AUTOSAR XML (schema 00045)
package /Med
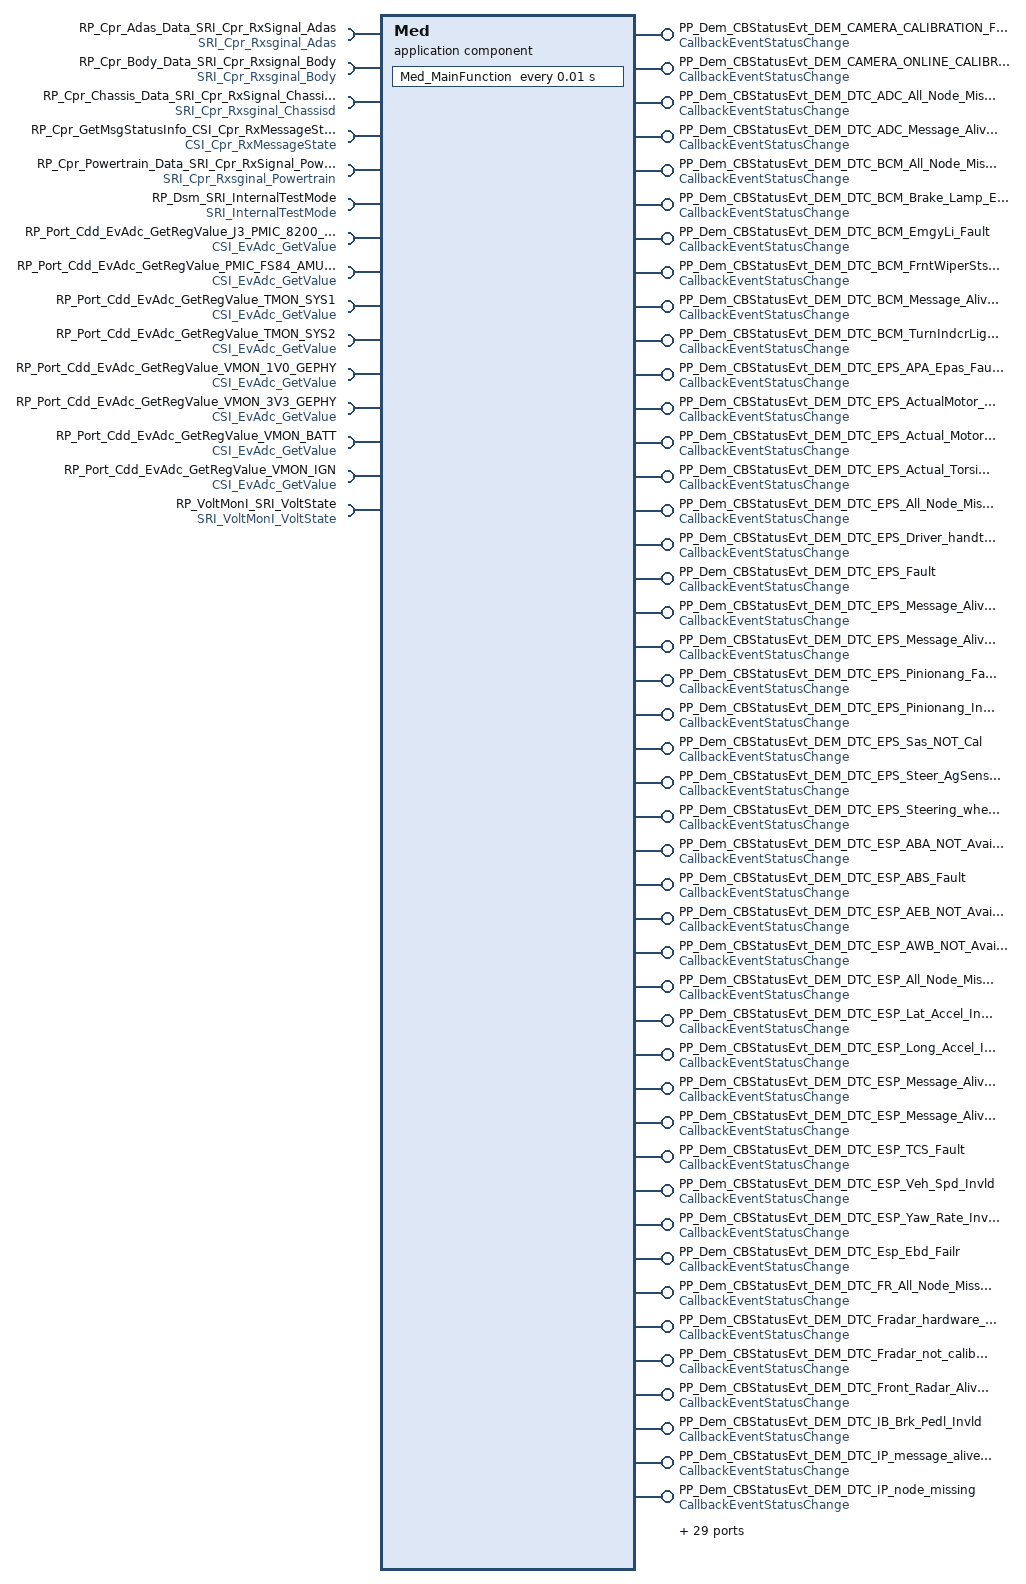
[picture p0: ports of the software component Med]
  application sw component type Med  # Mcu Error Dection
    73 x provide port, all with provided-interface=CallbackEventStatusChange:
      PP_Dem_CBStatusEvt_DEM_CAMERA_CALIBRATION_FAILURE
      PP_Dem_CBStatusEvt_DEM_CAMERA_ONLINE_CALIBRATION_FAILURE
      PP_Dem_CBStatusEvt_DEM_DTC_ADC_All_Node_Missing
      PP_Dem_CBStatusEvt_DEM_DTC_ADC_Message_Alive_Counter_Error
      PP_Dem_CBStatusEvt_DEM_DTC_BCM_All_Node_Missing
      PP_Dem_CBStatusEvt_DEM_DTC_BCM_Brake_Lamp_Error
      PP_Dem_CBStatusEvt_DEM_DTC_BCM_EmgyLi_Fault
      PP_Dem_CBStatusEvt_DEM_DTC_BCM_FrntWiperSts_Fault
      PP_Dem_CBStatusEvt_DEM_DTC_BCM_Message_Alive_Counter_Error_40ms
      PP_Dem_CBStatusEvt_DEM_DTC_BCM_TurnIndcrLight_Fault
      PP_Dem_CBStatusEvt_DEM_DTC_EPS_APA_Epas_Fault
      PP_Dem_CBStatusEvt_DEM_DTC_EPS_ActualMotor_Invld
      PP_Dem_CBStatusEvt_DEM_DTC_EPS_Actual_Motor_Torq_Invld
      PP_Dem_CBStatusEvt_DEM_DTC_EPS_Actual_TorsionTorq_Invld
      PP_Dem_CBStatusEvt_DEM_DTC_EPS_All_Node_Missing
      PP_Dem_CBStatusEvt_DEM_DTC_EPS_Driver_handtorque_invalid
      PP_Dem_CBStatusEvt_DEM_DTC_EPS_Fault
      PP_Dem_CBStatusEvt_DEM_DTC_EPS_Message_Alive_Counter_Error_10ms
      PP_Dem_CBStatusEvt_DEM_DTC_EPS_Message_Alive_Counter_Error_20ms
      PP_Dem_CBStatusEvt_DEM_DTC_EPS_Pinionang_Fault
      PP_Dem_CBStatusEvt_DEM_DTC_EPS_Pinionang_Invld
      PP_Dem_CBStatusEvt_DEM_DTC_EPS_Sas_NOT_Cal
      PP_Dem_CBStatusEvt_DEM_DTC_EPS_Steer_AgSens_Fault
      PP_Dem_CBStatusEvt_DEM_DTC_EPS_Steering_wheelvibration_failure
      PP_Dem_CBStatusEvt_DEM_DTC_ESP_ABA_NOT_Available
      PP_Dem_CBStatusEvt_DEM_DTC_ESP_ABS_Fault
      PP_Dem_CBStatusEvt_DEM_DTC_ESP_AEB_NOT_Available
      PP_Dem_CBStatusEvt_DEM_DTC_ESP_AWB_NOT_Available
      PP_Dem_CBStatusEvt_DEM_DTC_ESP_All_Node_Missing
      PP_Dem_CBStatusEvt_DEM_DTC_ESP_Lat_Accel_Invld
      PP_Dem_CBStatusEvt_DEM_DTC_ESP_Long_Accel_Invld
      PP_Dem_CBStatusEvt_DEM_DTC_ESP_Message_Alive_Counter_Error
      PP_Dem_CBStatusEvt_DEM_DTC_ESP_Message_Alive_Counter_Error_100ms
      PP_Dem_CBStatusEvt_DEM_DTC_ESP_TCS_Fault
      PP_Dem_CBStatusEvt_DEM_DTC_ESP_Veh_Spd_Invld
      PP_Dem_CBStatusEvt_DEM_DTC_ESP_Yaw_Rate_Invld
      PP_Dem_CBStatusEvt_DEM_DTC_Esp_Ebd_Failr
      PP_Dem_CBStatusEvt_DEM_DTC_FR_All_Node_Missing
      PP_Dem_CBStatusEvt_DEM_DTC_Fradar_hardware_error
      PP_Dem_CBStatusEvt_DEM_DTC_Fradar_not_calibration_or_blockage
      PP_Dem_CBStatusEvt_DEM_DTC_Front_Radar_Alive_Counter_Error
      PP_Dem_CBStatusEvt_DEM_DTC_IB_Brk_Pedl_Invld
      PP_Dem_CBStatusEvt_DEM_DTC_IP_message_alive_counter_error
      PP_Dem_CBStatusEvt_DEM_DTC_IP_node_missing
      PP_Dem_CBStatusEvt_DEM_DTC_IP_warning_invalid
      PP_Dem_CBStatusEvt_DEM_DTC_J3_Camera_Blockage
      PP_Dem_CBStatusEvt_DEM_DTC_J3_Camera_Error
      PP_Dem_CBStatusEvt_DEM_DTC_J3_SOC_CPU_Error_PWM_Missing
      PP_Dem_CBStatusEvt_DEM_DTC_J3_SOC_Perception_Error
      PP_Dem_CBStatusEvt_DEM_DTC_J3_SOC_Safetylib_Error
      PP_Dem_CBStatusEvt_DEM_DTC_J3_SOC_System_Service_Error
      PP_Dem_CBStatusEvt_DEM_DTC_J3_Time_Sync_Error
      PP_Dem_CBStatusEvt_DEM_DTC_MCU_TEMP_INITIAL_HIGH
      PP_Dem_CBStatusEvt_DEM_DTC_Private_CAN_Bus_Off
      PP_Dem_CBStatusEvt_DEM_DTC_Public_CAN_Bus_Off
      PP_Dem_CBStatusEvt_DEM_DTC_RLR_Message_Alive_Counter_Error
      PP_Dem_CBStatusEvt_DEM_DTC_SRS_All_Node_Missing
      PP_Dem_CBStatusEvt_DEM_DTC_SRS_Drvr_BucSwt_Invld
      PP_Dem_CBStatusEvt_DEM_DTC_SRS_Message_Alive_Counter_Error
      PP_Dem_CBStatusEvt_DEM_DTC_VCU_Accr_Pedl_Posn_Invld
      PP_Dem_CBStatusEvt_DEM_DTC_VCU_All_Node_Missing
      PP_Dem_CBStatusEvt_DEM_DTC_VCU_Gear_Posn_Invld
      PP_Dem_CBStatusEvt_DEM_DTC_VCU_Message_Alive_Counter_Error
      PP_Dem_CBStatusEvt_DEM_DTC_Whl_Spd_Data_Invld
      PP_Dem_CBStatusEvt_DEM_DTC_Whl_Spd_Dir_Invld
      PP_Dem_CBStatusEvt_DEM_DTC_Whl_Spd_Pls_Invld
      PP_Dem_CBStatusEvt_DEM_J3_SYS_KERNEL_SW
      PP_Dem_CBStatusEvt_DEM_MCU_TEMP_EXT_HIGH
      PP_Dem_CBStatusEvt_DEM_MCU_TEMP_EXT_LOW
      PP_Dem_CBStatusEvt_DEM_SOCJ3_TEMP_EXT_HIGH
      PP_Dem_CBStatusEvt_DEM_VMON_BATT_HIGH
      PP_Dem_CBStatusEvt_DEM_VMON_BATT_LOW
      PP_Dem_CBStatusEvt_SPI_E_HARDWARE_ERROR
    15 x require port:
      RP_Cpr_Adas_Data_SRI_Cpr_RxSignal_Adas: required-interface=SRI_Cpr_Rxsginal_Adas
      RP_Cpr_Body_Data_SRI_Cpr_Rxsignal_Body: required-interface=SRI_Cpr_Rxsginal_Body
      RP_Cpr_Chassis_Data_SRI_Cpr_RxSignal_Chassisd: required-interface=SRI_Cpr_Rxsginal_Chassisd
      RP_Cpr_GetMsgStatusInfo_CSI_Cpr_RxMessageState: required-interface=CSI_Cpr_RxMessageState
      RP_Cpr_Powertrain_Data_SRI_Cpr_RxSignal_Powertrain: required-interface=SRI_Cpr_Rxsginal_Powertrain
      RP_Dsm_SRI_InternalTestMode: required-interface=SRI_InternalTestMode
      RP_Port_Cdd_EvAdc_GetRegValue_J3_PMIC_8200_AMUX_OUT: required-interface=CSI_EvAdc_GetValue
      RP_Port_Cdd_EvAdc_GetRegValue_PMIC_FS84_AMUX_OUT0: required-interface=CSI_EvAdc_GetValue
      RP_Port_Cdd_EvAdc_GetRegValue_TMON_SYS1: required-interface=CSI_EvAdc_GetValue
      RP_Port_Cdd_EvAdc_GetRegValue_TMON_SYS2: required-interface=CSI_EvAdc_GetValue
      RP_Port_Cdd_EvAdc_GetRegValue_VMON_1V0_GEPHY: required-interface=CSI_EvAdc_GetValue
      RP_Port_Cdd_EvAdc_GetRegValue_VMON_3V3_GEPHY: required-interface=CSI_EvAdc_GetValue
      RP_Port_Cdd_EvAdc_GetRegValue_VMON_BATT: required-interface=CSI_EvAdc_GetValue
      RP_Port_Cdd_EvAdc_GetRegValue_VMON_IGN: required-interface=CSI_EvAdc_GetValue
      RP_VoltMonI_SRI_VoltState: required-interface=SRI_VoltMonI_VoltState
    behavior Med_IB: handle-termination-and-restart=NO-SUPPORT
      init event InitEvent_Med_InitFunction: start-on-event=Med_InitFunction
      timing event TimingEvent_Med_Mainfunction: start-on-event=Med_MainFunction, period=0.01
      73 x operation invoked event:
        oie_PP_Dem_CBStatusEvt_DEM_CAMERA_CALIBRATION_FAILURE_EventStatusChanged: start-on-event=Med_u_CBStatusEvt_DEM_CAMERA_CALIBRATION_FAILURE, operation=PP_Dem_CBStatusEvt_DEM_CAMERA_CALIBRATION_FAILURE.EventStatusChanged
        oie_PP_Dem_CBStatusEvt_DEM_CAMERA_ONLINE_CALIBRATION_FAILURE_EventStatusChanged: start-on-event=Med_u_CBStatusEvt_DEM_CAMERA_ONLINE_CALIBRATION_FAILURE, operation=PP_Dem_CBStatusEvt_DEM_CAMERA_ONLINE_CALIBRATION_FAILURE.EventStatusChanged
        oie_PP_Dem_CBStatusEvt_DEM_DTC_ADC_All_Node_Missing_EventStatusChanged: start-on-event=Med_u_CBStatusEvt_DEM_DTC_ADC_All_Node_Missing, operation=PP_Dem_CBStatusEvt_DEM_DTC_ADC_All_Node_Missing.EventStatusChanged
        oie_PP_Dem_CBStatusEvt_DEM_DTC_ADC_Message_Alive_Counter_Error_EventStatusChanged: start-on-event=Med_u_CBStatusEvt_DEM_DTC_ADC_Message_Alive_Counter_Error, operation=PP_Dem_CBStatusEvt_DEM_DTC_ADC_Message_Alive_Counter_Error.EventStatusChanged
        oie_PP_Dem_CBStatusEvt_DEM_DTC_BCM_All_Node_Missing_EventStatusChanged: start-on-event=Med_u_CBStatusEvt_DEM_DTC_BCM_All_Node_Missing, operation=PP_Dem_CBStatusEvt_DEM_DTC_BCM_All_Node_Missing.EventStatusChanged
        oie_PP_Dem_CBStatusEvt_DEM_DTC_BCM_Brake_Lamp_Error_EventStatusChanged: start-on-event=Med_u_CBStatusEvt_DEM_DTC_BCM_Brake_Lamp_Error, operation=PP_Dem_CBStatusEvt_DEM_DTC_BCM_Brake_Lamp_Error.EventStatusChanged
        oie_PP_Dem_CBStatusEvt_DEM_DTC_BCM_EmgyLi_Fault_EventStatusChanged: start-on-event=Med_u_CBStatusEvt_DEM_DTC_BCM_EmgyLi_Fault, operation=PP_Dem_CBStatusEvt_DEM_DTC_BCM_EmgyLi_Fault.EventStatusChanged
        oie_PP_Dem_CBStatusEvt_DEM_DTC_BCM_FrntWiperSts_Fault_EventStatusChanged: start-on-event=Med_u_CBStatusEvt_DEM_DTC_BCM_FrntWiperSts_Fault, operation=PP_Dem_CBStatusEvt_DEM_DTC_BCM_FrntWiperSts_Fault.EventStatusChanged
        oie_PP_Dem_CBStatusEvt_DEM_DTC_BCM_Message_Alive_Counter_Error_40ms_EventStatusChanged: start-on-event=Med_u_CBStatusEvt_DEM_DTC_BCM_Message_Alive_Counter_Error_40ms, operation=PP_Dem_CBStatusEvt_DEM_DTC_BCM_Message_Alive_Counter_Error_40ms.EventStatusChanged
        oie_PP_Dem_CBStatusEvt_DEM_DTC_BCM_Turn_Indcr_Light_Fault_EventStatusChanged: start-on-event=Med_u_CBStatusEvt_DEM_DTC_BCM_TurnIndcrLight_Fault, operation=PP_Dem_CBStatusEvt_DEM_DTC_BCM_TurnIndcrLight_Fault.EventStatusChanged
        oie_PP_Dem_CBStatusEvt_DEM_DTC_EPS_APA_Epas_Fault_EventStatusChanged: start-on-event=Med_u_CBStatusEvt_DEM_DTC_EPS_APA_Epas_Fault, operation=PP_Dem_CBStatusEvt_DEM_DTC_EPS_APA_Epas_Fault.EventStatusChanged
        oie_PP_Dem_CBStatusEvt_DEM_DTC_EPS_ActualMotor_Invld_EventStatusChanged: start-on-event=Med_u_CBStatusEvt_DEM_DTC_EPS_ActualMotor_Invld, operation=PP_Dem_CBStatusEvt_DEM_DTC_EPS_ActualMotor_Invld.EventStatusChanged
        oie_PP_Dem_CBStatusEvt_DEM_DTC_EPS_Actual_Motor_Torq_Invld_EventStatusChanged: start-on-event=Med_u_CBStatusEvt_DEM_DTC_EPS_Actual_Motor_Torq_Invld, operation=PP_Dem_CBStatusEvt_DEM_DTC_EPS_Actual_Motor_Torq_Invld.EventStatusChanged
        oie_PP_Dem_CBStatusEvt_DEM_DTC_EPS_Actual_TorsionTorq_Invld_EventStatusChanged: start-on-event=Med_u_CBStatusEvt_DEM_DTC_EPS_Actual_TorsionTorq_Invld, operation=PP_Dem_CBStatusEvt_DEM_DTC_EPS_Actual_TorsionTorq_Invld.EventStatusChanged
        oie_PP_Dem_CBStatusEvt_DEM_DTC_EPS_All_Node_Missing_EventStatusChanged: start-on-event=Med_u_CBStatusEvt_DEM_DTC_EPS_All_Node_Missing, operation=PP_Dem_CBStatusEvt_DEM_DTC_EPS_All_Node_Missing.EventStatusChanged
        oie_PP_Dem_CBStatusEvt_DEM_DTC_EPS_Driver_handtorque_invalid_EventStatusChanged: start-on-event=Med_u_CBStatusEvt_DEM_DTC_EPS_Driver_handtorque_invalid, operation=PP_Dem_CBStatusEvt_DEM_DTC_EPS_Driver_handtorque_invalid.EventStatusChanged
        oie_PP_Dem_CBStatusEvt_DEM_DTC_EPS_Fault_EventStatusChanged: start-on-event=Med_u_CBStatusEvt_DEM_DTC_EPS_Fault, operation=PP_Dem_CBStatusEvt_DEM_DTC_EPS_Fault.EventStatusChanged
        oie_PP_Dem_CBStatusEvt_DEM_DTC_EPS_Message_Alive_Counter_Error_10ms_EventStatusChanged: start-on-event=Med_u_CBStatusEvt_DEM_DTC_EPS_Message_Alive_Counter_Error_10ms, operation=PP_Dem_CBStatusEvt_DEM_DTC_EPS_Message_Alive_Counter_Error_10ms.EventStatusChanged
        oie_PP_Dem_CBStatusEvt_DEM_DTC_EPS_Message_Alive_Counter_Error_20ms_EventStatusChanged: start-on-event=Med_u_CBStatusEvt_DEM_DTC_EPS_Message_Alive_Counter_Error_20ms, operation=PP_Dem_CBStatusEvt_DEM_DTC_EPS_Message_Alive_Counter_Error_20ms.EventStatusChanged
        oie_PP_Dem_CBStatusEvt_DEM_DTC_EPS_Pinionang_Fault_EventStatusChanged: start-on-event=Med_u_CBStatusEvt_DEM_DTC_EPS_Pinionang_Fault, operation=PP_Dem_CBStatusEvt_DEM_DTC_EPS_Pinionang_Fault.EventStatusChanged
        oie_PP_Dem_CBStatusEvt_DEM_DTC_EPS_Pinionang_Invld_EventStatusChanged: start-on-event=Med_u_CBStatusEvt_DEM_DTC_EPS_Pinionang_Invld, operation=PP_Dem_CBStatusEvt_DEM_DTC_EPS_Pinionang_Invld.EventStatusChanged
        oie_PP_Dem_CBStatusEvt_DEM_DTC_EPS_Sas_NOT_Cal_EventStatusChanged: start-on-event=Med_u_CBStatusEvt_DEM_DTC_EPS_Sas_NOT_Cal, operation=PP_Dem_CBStatusEvt_DEM_DTC_EPS_Sas_NOT_Cal.EventStatusChanged
        oie_PP_Dem_CBStatusEvt_DEM_DTC_EPS_Steer_AgSens_Fault_EventStatusChanged: start-on-event=Med_u_CBStatusEvt_DEM_DTC_EPS_Steer_AgSens_Fault, operation=PP_Dem_CBStatusEvt_DEM_DTC_EPS_Steer_AgSens_Fault.EventStatusChanged
        oie_PP_Dem_CBStatusEvt_DEM_DTC_EPS_Steering_wheelvibration_failure_EventStatusChanged: start-on-event=Med_u_CBStatusEvt_DEM_DTC_EPS_Steering_wheelvibration_failure, operation=PP_Dem_CBStatusEvt_DEM_DTC_EPS_Steering_wheelvibration_failure.EventStatusChanged
        oie_PP_Dem_CBStatusEvt_DEM_DTC_ESP_ABA_NOT_Available_EventStatusChanged: start-on-event=Med_u_CBStatusEvt_DEM_DTC_ESP_ABA_NOT_Available, operation=PP_Dem_CBStatusEvt_DEM_DTC_ESP_ABA_NOT_Available.EventStatusChanged
        oie_PP_Dem_CBStatusEvt_DEM_DTC_ESP_ABS_Fault_EventStatusChanged: start-on-event=Med_u_CBStatusEvt_DEM_DTC_ESP_ABS_Fault, operation=PP_Dem_CBStatusEvt_DEM_DTC_ESP_ABS_Fault.EventStatusChanged
        oie_PP_Dem_CBStatusEvt_DEM_DTC_ESP_AEB_NOT_Available_EventStatusChanged: start-on-event=Med_u_CBStatusEvt_DEM_DTC_ESP_AEB_NOT_Available, operation=PP_Dem_CBStatusEvt_DEM_DTC_ESP_AEB_NOT_Available.EventStatusChanged
        oie_PP_Dem_CBStatusEvt_DEM_DTC_ESP_AWB_NOT_Available_EventStatusChanged: start-on-event=Med_u_CBStatusEvt_DEM_DTC_ESP_AWB_NOT_Available, operation=PP_Dem_CBStatusEvt_DEM_DTC_ESP_AWB_NOT_Available.EventStatusChanged
        oie_PP_Dem_CBStatusEvt_DEM_DTC_ESP_All_Node_Missing_EventStatusChanged: start-on-event=Med_u_CBStatusEvt_DEM_DTC_ESP_All_Node_Missing, operation=PP_Dem_CBStatusEvt_DEM_DTC_ESP_All_Node_Missing.EventStatusChanged
        oie_PP_Dem_CBStatusEvt_DEM_DTC_ESP_Lat_Accel_Invld_EventStatusChanged: start-on-event=Med_u_CBStatusEvt_DEM_DTC_ESP_Lat_Accel_Invld, operation=PP_Dem_CBStatusEvt_DEM_DTC_ESP_Lat_Accel_Invld.EventStatusChanged
        oie_PP_Dem_CBStatusEvt_DEM_DTC_ESP_Long_Accel_Invld_EventStatusChanged: start-on-event=Med_u_CBStatusEvt_DEM_DTC_ESP_Long_Accel_Invld, operation=PP_Dem_CBStatusEvt_DEM_DTC_ESP_Long_Accel_Invld.EventStatusChanged
        oie_PP_Dem_CBStatusEvt_DEM_DTC_ESP_Message_Alive_Counter_Error_100ms_EventStatusChanged: start-on-event=Med_u_CBStatusEvt_DEM_DTC_ESP_Message_Alive_Counter_Error_100ms, operation=PP_Dem_CBStatusEvt_DEM_DTC_ESP_Message_Alive_Counter_Error_100ms.EventStatusChanged
        oie_PP_Dem_CBStatusEvt_DEM_DTC_ESP_Message_Alive_Counter_Error_EventStatusChanged: start-on-event=Med_u_CBStatusEvt_DEM_DTC_ESP_Message_Alive_Counter_Error, operation=PP_Dem_CBStatusEvt_DEM_DTC_ESP_Message_Alive_Counter_Error.EventStatusChanged
        oie_PP_Dem_CBStatusEvt_DEM_DTC_ESP_TCS_Fault_EventStatusChanged: start-on-event=Med_u_CBStatusEvt_DEM_DTC_ESP_TCS_Fault, operation=PP_Dem_CBStatusEvt_DEM_DTC_ESP_TCS_Fault.EventStatusChanged
        oie_PP_Dem_CBStatusEvt_DEM_DTC_ESP_Veh_Spd_Invld_EventStatusChanged: start-on-event=Med_u_CBStatusEvt_DEM_DTC_ESP_Veh_Spd_Invld, operation=PP_Dem_CBStatusEvt_DEM_DTC_ESP_Veh_Spd_Invld.EventStatusChanged
        oie_PP_Dem_CBStatusEvt_DEM_DTC_ESP_Yaw_Rate_Invld_EventStatusChanged: start-on-event=Med_u_CBStatusEvt_DEM_DTC_ESP_Yaw_Rate_Invld, operation=PP_Dem_CBStatusEvt_DEM_DTC_ESP_Yaw_Rate_Invld.EventStatusChanged
        oie_PP_Dem_CBStatusEvt_DEM_DTC_Esp_Ebd_Failr_EventStatusChanged: start-on-event=Med_u_CBStatusEvt_DEM_DTC_ESP_Ebd_Failr, operation=PP_Dem_CBStatusEvt_DEM_DTC_Esp_Ebd_Failr.EventStatusChanged
        oie_PP_Dem_CBStatusEvt_DEM_DTC_FR_All_Node_Missing_EventStatusChanged: start-on-event=Med_u_CBStatusEvt_DEM_DTC_FR_All_Node_Missing, operation=PP_Dem_CBStatusEvt_DEM_DTC_FR_All_Node_Missing.EventStatusChanged
        oie_PP_Dem_CBStatusEvt_DEM_DTC_Fradar_hardware_error_EventStatusChanged: start-on-event=Med_u_CBStatusEvt_DEM_DTC_Fradar_hardware_error, operation=PP_Dem_CBStatusEvt_DEM_DTC_Fradar_hardware_error.EventStatusChanged
        oie_PP_Dem_CBStatusEvt_DEM_DTC_Fradar_not_calibration_or_blockage_EventStatusChanged: start-on-event=Med_u_CBStatusEvt_DEM_DTC_Fradar_not_calibration_or_blockage, operation=PP_Dem_CBStatusEvt_DEM_DTC_Fradar_not_calibration_or_blockage.EventStatusChanged
        oie_PP_Dem_CBStatusEvt_DEM_DTC_Front_Radar_Alive_Counter_Error_EventStatusChanged: start-on-event=Med_u_CBStatusEvt_DEM_DTC_Front_Radar_Alive_Counter_Error, operation=PP_Dem_CBStatusEvt_DEM_DTC_Front_Radar_Alive_Counter_Error.EventStatusChanged
        oie_PP_Dem_CBStatusEvt_DEM_DTC_IB_Brk_Pedl_Invld_EventStatusChanged: start-on-event=Med_u_CBStatusEvt_DEM_DTC_IB_Brk_Pedl_Invld, operation=PP_Dem_CBStatusEvt_DEM_DTC_IB_Brk_Pedl_Invld.EventStatusChanged
        oie_PP_Dem_CBStatusEvt_DEM_DTC_IP_message_alive_counter_error_EventStatusChanged: start-on-event=Med_u_CBStatusEvt_DEM_DTC_IP_message_alive_counter_error, operation=PP_Dem_CBStatusEvt_DEM_DTC_IP_message_alive_counter_error.EventStatusChanged
        oie_PP_Dem_CBStatusEvt_DEM_DTC_IP_node_missing_EventStatusChanged: start-on-event=Med_u_CBStatusEvt_DEM_DTC_IP_node_missing, operation=PP_Dem_CBStatusEvt_DEM_DTC_IP_node_missing.EventStatusChanged
        oie_PP_Dem_CBStatusEvt_DEM_DTC_IP_warning_invalid_EventStatusChanged: start-on-event=Med_u_CBStatusEvt_DEM_DTC_IP_warning_invalid, operation=PP_Dem_CBStatusEvt_DEM_DTC_IP_warning_invalid.EventStatusChanged
        oie_PP_Dem_CBStatusEvt_DEM_DTC_J3_Camera_Blockage_EventStatusChanged: start-on-event=Med_u_CBStatusEvt_DEM_DTC_J3_Camera_Blockage, operation=PP_Dem_CBStatusEvt_DEM_DTC_J3_Camera_Blockage.EventStatusChanged
        oie_PP_Dem_CBStatusEvt_DEM_DTC_J3_Camera_Error_EventStatusChanged: start-on-event=Med_u_CBStatusEvt_DEM_DTC_J3_Camera_Error, operation=PP_Dem_CBStatusEvt_DEM_DTC_J3_Camera_Error.EventStatusChanged
        oie_PP_Dem_CBStatusEvt_DEM_DTC_J3_SOC_CPU_Error_PWM_Missing_EventStatusChanged: start-on-event=Med_u_CBStatusEvt_DEM_DTC_J3_SOC_CPU_Error_PWM_Missing, operation=PP_Dem_CBStatusEvt_DEM_DTC_J3_SOC_CPU_Error_PWM_Missing.EventStatusChanged
        oie_PP_Dem_CBStatusEvt_DEM_DTC_J3_SOC_Perception_Error_EventStatusChanged: start-on-event=Med_u_CBStatusEvt_DEM_DTC_J3_SOC_Perception_Error, operation=PP_Dem_CBStatusEvt_DEM_DTC_J3_SOC_Perception_Error.EventStatusChanged
        oie_PP_Dem_CBStatusEvt_DEM_DTC_J3_SOC_Safetylib_Error_EventStatusChanged: start-on-event=Med_u_CBStatusEvt_DEM_DTC_J3_SOC_Safetylib_Error, operation=PP_Dem_CBStatusEvt_DEM_DTC_J3_SOC_Safetylib_Error.EventStatusChanged
        oie_PP_Dem_CBStatusEvt_DEM_DTC_J3_SOC_System_Service_Error_EventStatusChanged: start-on-event=Med_u_CBStatusEvt_DEM_DTC_J3_SOC_System_Service_Error, operation=PP_Dem_CBStatusEvt_DEM_DTC_J3_SOC_System_Service_Error.EventStatusChanged
        oie_PP_Dem_CBStatusEvt_DEM_DTC_J3_Time_Sync_Error_EventStatusChanged: start-on-event=Med_u_CBStatusEvt_DEM_DTC_J3_Time_Sync_Error, operation=PP_Dem_CBStatusEvt_DEM_DTC_J3_Time_Sync_Error.EventStatusChanged
        oie_PP_Dem_CBStatusEvt_DEM_DTC_MCU_TEMP_INITIAL_HIGH_EventStatusChanged: start-on-event=Med_u_CBStatusEvt_DEM_DTC_MCU_TEMP_INITIAL_HIGH, operation=PP_Dem_CBStatusEvt_DEM_DTC_MCU_TEMP_INITIAL_HIGH.EventStatusChanged
        oie_PP_Dem_CBStatusEvt_DEM_DTC_Private_CAN_Bus_Off_EventStatusChanged: start-on-event=Med_u_CBStatusEvt_DEM_DTC_Private_CAN_Bus_Off, operation=PP_Dem_CBStatusEvt_DEM_DTC_Private_CAN_Bus_Off.EventStatusChanged
        oie_PP_Dem_CBStatusEvt_DEM_DTC_Public_CAN_Bus_Off_EventStatusChanged: start-on-event=Med_u_CBStatusEvt_DEM_DTC_Public_CAN_Bus_Off, operation=PP_Dem_CBStatusEvt_DEM_DTC_Public_CAN_Bus_Off.EventStatusChanged
        oie_PP_Dem_CBStatusEvt_DEM_DTC_RLR_Message_Alive_Counter_Error_EventStatusChanged: start-on-event=Med_u_CBStatusEvt_DEM_DTC_RLR_Message_Alive_Counter_Error, operation=PP_Dem_CBStatusEvt_DEM_DTC_RLR_Message_Alive_Counter_Error.EventStatusChanged
        oie_PP_Dem_CBStatusEvt_DEM_DTC_SRS_All_Node_Missing_EventStatusChanged: start-on-event=Med_u_CBStatusEvt_DEM_DTC_SRS_All_Node_Missing, operation=PP_Dem_CBStatusEvt_DEM_DTC_SRS_All_Node_Missing.EventStatusChanged
        oie_PP_Dem_CBStatusEvt_DEM_DTC_SRS_Drvr_BucSwt_Invld_EventStatusChanged: start-on-event=Med_u_CBStatusEvt_DEM_DTC_SRS_Drvr_BucSwt_Invld, operation=PP_Dem_CBStatusEvt_DEM_DTC_SRS_Drvr_BucSwt_Invld.EventStatusChanged
        oie_PP_Dem_CBStatusEvt_DEM_DTC_SRS_Message_Alive_Counter_Error_EventStatusChanged: start-on-event=Med_u_CBStatusEvt_DEM_DTC_SRS_Message_Alive_Counter_Error, operation=PP_Dem_CBStatusEvt_DEM_DTC_SRS_Message_Alive_Counter_Error.EventStatusChanged
        oie_PP_Dem_CBStatusEvt_DEM_DTC_VCU_Accr_Pedl_Posn_Invld_EventStatusChanged: start-on-event=Med_u_CBStatusEvt_DEM_DTC_VCU_Accr_Pedl_Posn_Invld, operation=PP_Dem_CBStatusEvt_DEM_DTC_VCU_Accr_Pedl_Posn_Invld.EventStatusChanged
        oie_PP_Dem_CBStatusEvt_DEM_DTC_VCU_All_Node_Missing_EventStatusChanged: start-on-event=Med_u_CBStatusEvt_DEM_DTC_VCU_All_Node_Missing, operation=PP_Dem_CBStatusEvt_DEM_DTC_VCU_All_Node_Missing.EventStatusChanged
        oie_PP_Dem_CBStatusEvt_DEM_DTC_VCU_Gear_Posn_Invld_EventStatusChanged: start-on-event=Med_u_CBStatusEvt_DEM_DTC_VCU_Gear_Posn_Invld, operation=PP_Dem_CBStatusEvt_DEM_DTC_VCU_Gear_Posn_Invld.EventStatusChanged
        oie_PP_Dem_CBStatusEvt_DEM_DTC_VCU_Message_Alive_Counter_Error_EventStatusChanged: start-on-event=Med_u_CBStatusEvt_DEM_DTC_VCU_Message_Alive_Counter_Error, operation=PP_Dem_CBStatusEvt_DEM_DTC_VCU_Message_Alive_Counter_Error.EventStatusChanged
        oie_PP_Dem_CBStatusEvt_DEM_DTC_Whl_Spd_Data_Invld_EventStatusChanged: start-on-event=Med_u_CBStatusEvt_DEM_DTC_Whl_Spd_Data_Invld, operation=PP_Dem_CBStatusEvt_DEM_DTC_Whl_Spd_Data_Invld.EventStatusChanged
        oie_PP_Dem_CBStatusEvt_DEM_DTC_Whl_Spd_Dir_Invld_EventStatusChanged: start-on-event=Med_u_CBStatusEvt_DEM_DTC_Whl_Spd_Dir_Invld, operation=PP_Dem_CBStatusEvt_DEM_DTC_Whl_Spd_Dir_Invld.EventStatusChanged
        oie_PP_Dem_CBStatusEvt_DEM_DTC_Whl_Spd_Pls_Invld_EventStatusChanged: start-on-event=Med_u_CBStatusEvt_DEM_DTC_Whl_Spd_Pls_Invld, operation=PP_Dem_CBStatusEvt_DEM_DTC_Whl_Spd_Pls_Invld.EventStatusChanged
        oie_PP_Dem_CBStatusEvt_DEM_J3_SYS_KERNEL_SW_EventStatusChanged: start-on-event=Med_u_CBStatusEvt_DEM_J3_SYS_KERNEL_SW, operation=PP_Dem_CBStatusEvt_DEM_J3_SYS_KERNEL_SW.EventStatusChanged
        oie_PP_Dem_CBStatusEvt_DEM_MCU_TEMP_EXT_HIGH_EventStatusChanged: start-on-event=Med_u_CBStatusEvt_DEM_MCU_TEMP_EXT_HIGH, operation=PP_Dem_CBStatusEvt_DEM_MCU_TEMP_EXT_HIGH.EventStatusChanged
        oie_PP_Dem_CBStatusEvt_DEM_MCU_TEMP_EXT_LOW_EventStatusChanged: start-on-event=Med_u_CBStatusEvt_DEM_MCU_TEMP_EXT_LOW, operation=PP_Dem_CBStatusEvt_DEM_MCU_TEMP_EXT_LOW.EventStatusChanged
        oie_PP_Dem_CBStatusEvt_DEM_SOCJ3_TEMP_EXT_HIGH_EventStatusChanged: start-on-event=Med_u_CBStatusEvt_DEM_SOCJ3_TEMP_EXT_HIGH, operation=PP_Dem_CBStatusEvt_DEM_SOCJ3_TEMP_EXT_HIGH.EventStatusChanged
        oie_PP_Dem_CBStatusEvt_DEM_VMON_BATT_HIGH_EventStatusChanged: start-on-event=Med_u_CBStatusEvt_DEM_VMON_BATT_HIGH, operation=PP_Dem_CBStatusEvt_DEM_VMON_BATT_HIGH.EventStatusChanged
        oie_PP_Dem_CBStatusEvt_DEM_VMON_BATT_LOW_EventStatusChanged: start-on-event=Med_u_CBStatusEvt_DEM_VMON_BATT_LOW, operation=PP_Dem_CBStatusEvt_DEM_VMON_BATT_LOW.EventStatusChanged
        oie_PP_Dem_CBStatusEvt_SPI_E_HARDWARE_ERROR_EventStatusChanged: start-on-event=Med_u_CBStatusEvt_SPI_E_HARDWARE_ERROR, operation=PP_Dem_CBStatusEvt_SPI_E_HARDWARE_ERROR.EventStatusChanged
      75 x runnable:
        Med_InitFunction
        Med_MainFunction
          data-receive-point-by-arguments:
            93 x access:
              drparg_BCM_BrakeLampError: accessed-variable=RP_Cpr_Body_Data_SRI_Cpr_Rxsignal_Body.BCM_BrakeLampError
              drparg_BCM_BrakeLampError_St: accessed-variable=RP_Cpr_Body_Data_SRI_Cpr_Rxsignal_Body.BCM_BrakeLampError_Status
              drparg_BcmEmgyLiSts: accessed-variable=RP_Cpr_Body_Data_SRI_Cpr_Rxsignal_Body.BcmEmgyLiSts
              drparg_BcmEmgyLiSts_Status: accessed-variable=RP_Cpr_Body_Data_SRI_Cpr_Rxsignal_Body.BcmEmgyLiSts_Status
              drparg_BcmFrntWiperSts: accessed-variable=RP_Cpr_Body_Data_SRI_Cpr_Rxsignal_Body.BcmFrntWiperSts
              drparg_BcmFrntWiperSts_Status: accessed-variable=RP_Cpr_Body_Data_SRI_Cpr_Rxsignal_Body.BcmFrntWiperSts_Status
              drparg_BcmTurnIndcrLe: accessed-variable=RP_Cpr_Body_Data_SRI_Cpr_Rxsignal_Body.BcmTurnIndcrLe
              drparg_BcmTurnIndcrLe_Status: accessed-variable=RP_Cpr_Body_Data_SRI_Cpr_Rxsignal_Body.BcmTurnIndcrLe_Status
              drparg_BcmTurnIndcrRi: accessed-variable=RP_Cpr_Body_Data_SRI_Cpr_Rxsignal_Body.BcmTurnIndcrRi
              drparg_BcmTurnIndcrRi_Status: accessed-variable=RP_Cpr_Body_Data_SRI_Cpr_Rxsignal_Body.BcmTurnIndcrRi_Status
              drparg_DE_InternalTestMode: accessed-variable=RP_Dsm_SRI_InternalTestMode.DE_InternalTestMode
              drparg_DE_VoltMonI_VoltState: accessed-variable=RP_VoltMonI_SRI_VoltState.DE_VoltMonI_VoltState
              drparg_EPS_ActualMotorTorq: accessed-variable=RP_Cpr_Chassis_Data_SRI_Cpr_RxSignal_Chassisd.EPS_ActualMotorTorq
              drparg_EPS_ActualMotorTorq_S: accessed-variable=RP_Cpr_Chassis_Data_SRI_Cpr_RxSignal_Chassisd.EPS_ActualMotorTorq_Status
              drparg_EPS_ActualTorsionBarT: accessed-variable=RP_Cpr_Chassis_Data_SRI_Cpr_RxSignal_Chassisd.EPS_ActualTorsionBarTorq
              drparg_EPS_ActualTorsionBarT0: accessed-variable=RP_Cpr_Chassis_Data_SRI_Cpr_RxSignal_Chassisd.EPS_ActualTorsionBarTorq_Status
              drparg_EPS_fault_state: accessed-variable=RP_Cpr_Chassis_Data_SRI_Cpr_RxSignal_Chassisd.EPS_fault_state
              drparg_EPS_fault_state_Status: accessed-variable=RP_Cpr_Chassis_Data_SRI_Cpr_RxSignal_Chassisd.EPS_fault_state_Status
              drparg_ESP_LatAccelValid: accessed-variable=RP_Cpr_Chassis_Data_SRI_Cpr_RxSignal_Chassisd.ESP_LatAccelValid
              drparg_ESP_LongAccelValid: accessed-variable=RP_Cpr_Chassis_Data_SRI_Cpr_RxSignal_Chassisd.ESP_LongAccelValid
              drparg_ESP_YawRateValid: accessed-variable=RP_Cpr_Chassis_Data_SRI_Cpr_RxSignal_Chassisd.ESP_YawRateValid
              drparg_EpsConcussAvailabilit: accessed-variable=RP_Cpr_Chassis_Data_SRI_Cpr_RxSignal_Chassisd.EpsConcussAvailabilityStatus
              drparg_EpsConcussAvailabilit0: accessed-variable=RP_Cpr_Chassis_Data_SRI_Cpr_RxSignal_Chassisd.EpsConcussAvailabilityStatus_Status
              drparg_EpsFaild: accessed-variable=RP_Cpr_Chassis_Data_SRI_Cpr_RxSignal_Chassisd.EpsFaild
              drparg_EpsFaild_Status: accessed-variable=RP_Cpr_Chassis_Data_SRI_Cpr_RxSignal_Chassisd.EpsFaild_Status
              drparg_EpsMeasuredTorsionBar: accessed-variable=RP_Cpr_Chassis_Data_SRI_Cpr_RxSignal_Chassisd.EpsMeasuredTorsionBarTorque
              drparg_EpsMeasuredTorsionBar0: accessed-variable=RP_Cpr_Chassis_Data_SRI_Cpr_RxSignal_Chassisd.EpsMeasuredTorsionBarTorque_Status
              drparg_EpsPinionang: accessed-variable=RP_Cpr_Chassis_Data_SRI_Cpr_RxSignal_Chassisd.EpsPinionang
              drparg_EpsPinionang_Status: accessed-variable=RP_Cpr_Chassis_Data_SRI_Cpr_RxSignal_Chassisd.EpsPinionang_Status
              drparg_EpsSasCalSts: accessed-variable=RP_Cpr_Chassis_Data_SRI_Cpr_RxSignal_Chassisd.EpsSasCalSts
              drparg_EpsSasCalSts_Status: accessed-variable=RP_Cpr_Chassis_Data_SRI_Cpr_RxSignal_Chassisd.EpsSasCalSts_Status
              drparg_EpsSasSteerAg: accessed-variable=RP_Cpr_Chassis_Data_SRI_Cpr_RxSignal_Chassisd.EpsSasSteerAg
              drparg_EpsSasSteerAg_Status: accessed-variable=RP_Cpr_Chassis_Data_SRI_Cpr_RxSignal_Chassisd.EpsSasSteerAg_Status
              drparg_EspABAavailable: accessed-variable=RP_Cpr_Chassis_Data_SRI_Cpr_RxSignal_Chassisd.EspABAavailable
              drparg_EspABAavailable_Status: accessed-variable=RP_Cpr_Chassis_Data_SRI_Cpr_RxSignal_Chassisd.EspABAavailable_Status
              drparg_EspAEBAvailable: accessed-variable=RP_Cpr_Chassis_Data_SRI_Cpr_RxSignal_Chassisd.EspAEBAvailable
              drparg_EspAEBAvailable_Status: accessed-variable=RP_Cpr_Chassis_Data_SRI_Cpr_RxSignal_Chassisd.EspAEBAvailable_Status
              drparg_EspAWBavailable: accessed-variable=RP_Cpr_Chassis_Data_SRI_Cpr_RxSignal_Chassisd.EspAWBavailable
              drparg_EspAWBavailable_Status: accessed-variable=RP_Cpr_Chassis_Data_SRI_Cpr_RxSignal_Chassisd.EspAWBavailable_Status
              drparg_EspAbsFailr: accessed-variable=RP_Cpr_Chassis_Data_SRI_Cpr_RxSignal_Chassisd.EspAbsFailr
              drparg_EspAbsFailr_Status: accessed-variable=RP_Cpr_Chassis_Data_SRI_Cpr_RxSignal_Chassisd.EspAbsFailr_Status
              drparg_EspEbdFailr: accessed-variable=RP_Cpr_Chassis_Data_SRI_Cpr_RxSignal_Chassisd.EspEbdFailr
              drparg_EspEbdFailr_Status: accessed-variable=RP_Cpr_Chassis_Data_SRI_Cpr_RxSignal_Chassisd.EspEbdFailr_Status
              drparg_EspLatAccel: accessed-variable=RP_Cpr_Chassis_Data_SRI_Cpr_RxSignal_Chassisd.EspLatAccel
              drparg_EspLatAccel_Status: accessed-variable=RP_Cpr_Chassis_Data_SRI_Cpr_RxSignal_Chassisd.EspLatAccel_Status
              drparg_EspLongAccel: accessed-variable=RP_Cpr_Chassis_Data_SRI_Cpr_RxSignal_Chassisd.EspLongAccel
              drparg_EspLongAccel_Status: accessed-variable=RP_Cpr_Chassis_Data_SRI_Cpr_RxSignal_Chassisd.EspLongAccel_Status
              drparg_EspTcsFailr: accessed-variable=RP_Cpr_Chassis_Data_SRI_Cpr_RxSignal_Chassisd.EspTcsFailr
              drparg_EspTcsFailr_Status: accessed-variable=RP_Cpr_Chassis_Data_SRI_Cpr_RxSignal_Chassisd.EspTcsFailr_Status
              drparg_EspVehSpd: accessed-variable=RP_Cpr_Chassis_Data_SRI_Cpr_RxSignal_Chassisd.EspVehSpd
              drparg_EspVehSpd_Status: accessed-variable=RP_Cpr_Chassis_Data_SRI_Cpr_RxSignal_Chassisd.EspVehSpd_Status
              drparg_EspYawRate: accessed-variable=RP_Cpr_Chassis_Data_SRI_Cpr_RxSignal_Chassisd.EspYawRate
              drparg_EspYawRate_Status: accessed-variable=RP_Cpr_Chassis_Data_SRI_Cpr_RxSignal_Chassisd.EspYawRate_Status
              drparg_FR_RadarFailureStatus: accessed-variable=RP_Cpr_Adas_Data_SRI_Cpr_RxSignal_Adas.FR_RadarFailureStatus
              drparg_FR_RadarFailureStatus0: accessed-variable=RP_Cpr_Adas_Data_SRI_Cpr_RxSignal_Adas.FR_RadarFailureStatus_Status
              drparg_FRadarCalibrationStat: accessed-variable=RP_Cpr_Adas_Data_SRI_Cpr_RxSignal_Adas.FRadarCalibrationStatus
              drparg_FRadarCalibrationStat0: accessed-variable=RP_Cpr_Adas_Data_SRI_Cpr_RxSignal_Adas.FRadarCalibrationStatus_Status
              drparg_IP_DISFail: accessed-variable=RP_Cpr_Body_Data_SRI_Cpr_Rxsignal_Body.IP_DISFail
              drparg_IP_DISFail_Status: accessed-variable=RP_Cpr_Body_Data_SRI_Cpr_Rxsignal_Body.IP_DISFail_Status
              drparg_IP_QDashACCFail: accessed-variable=RP_Cpr_Body_Data_SRI_Cpr_Rxsignal_Body.IP_QDashACCFail
              drparg_IP_QDashACCFail_Status: accessed-variable=RP_Cpr_Body_Data_SRI_Cpr_Rxsignal_Body.IP_QDashACCFail_Status
              drparg_IbBrkPedlStsGb: accessed-variable=RP_Cpr_Chassis_Data_SRI_Cpr_RxSignal_Chassisd.IbBrkPedlStsGb
              drparg_IbBrkPedlStsGb_Status: accessed-variable=RP_Cpr_Chassis_Data_SRI_Cpr_RxSignal_Chassisd.IbBrkPedlStsGb_Status
              drparg_SrsDrvrBucSwtSts: accessed-variable=RP_Cpr_Body_Data_SRI_Cpr_Rxsignal_Body.SrsDrvrBucSwtSts
              drparg_SrsDrvrBucSwtSts_Stat: accessed-variable=RP_Cpr_Body_Data_SRI_Cpr_Rxsignal_Body.SrsDrvrBucSwtSts_Status
              drparg_VcuAccrPedlPosn: accessed-variable=RP_Cpr_Chassis_Data_SRI_Cpr_RxSignal_Chassisd.VcuAccrPedlPosn
              drparg_VcuAccrPedlPosn_Status: accessed-variable=RP_Cpr_Chassis_Data_SRI_Cpr_RxSignal_Chassisd.VcuAccrPedlPosn_Status
              drparg_VcuGearPosn: accessed-variable=RP_Cpr_Chassis_Data_SRI_Cpr_RxSignal_Chassisd.VcuGearPosn
              drparg_VcuGearPosn_Status: accessed-variable=RP_Cpr_Chassis_Data_SRI_Cpr_RxSignal_Chassisd.VcuGearPosn_Status
              drparg_WhlSpdFrntLePls: accessed-variable=RP_Cpr_Powertrain_Data_SRI_Cpr_RxSignal_Powertrain.WhlSpdFrntLePls
              drparg_WhlSpdFrntLePls_Status: accessed-variable=RP_Cpr_Powertrain_Data_SRI_Cpr_RxSignal_Powertrain.WhlSpdFrntLePls_Status
              drparg_WhlSpdFrntRiPls: accessed-variable=RP_Cpr_Powertrain_Data_SRI_Cpr_RxSignal_Powertrain.WhlSpdFrntRiPls
              drparg_WhlSpdFrntRiPls_Status: accessed-variable=RP_Cpr_Powertrain_Data_SRI_Cpr_RxSignal_Powertrain.WhlSpdFrntRiPls_Status
              drparg_WhlSpdLeFrntData: accessed-variable=RP_Cpr_Powertrain_Data_SRI_Cpr_RxSignal_Powertrain.WhlSpdLeFrntData
              drparg_WhlSpdLeFrntDataVld: accessed-variable=RP_Cpr_Powertrain_Data_SRI_Cpr_RxSignal_Powertrain.WhlSpdLeFrntDataVld
              drparg_WhlSpdLeFrntDir: accessed-variable=RP_Cpr_Powertrain_Data_SRI_Cpr_RxSignal_Powertrain.WhlSpdLeFrntDir
              drparg_WhlSpdLeFrntDir_Status: accessed-variable=RP_Cpr_Powertrain_Data_SRI_Cpr_RxSignal_Powertrain.WhlSpdLeFrntDir_Status
              drparg_WhlSpdLeReData: accessed-variable=RP_Cpr_Powertrain_Data_SRI_Cpr_RxSignal_Powertrain.WhlSpdLeReData
              drparg_WhlSpdLeReDataVld: accessed-variable=RP_Cpr_Powertrain_Data_SRI_Cpr_RxSignal_Powertrain.WhlSpdLeReDataVld
              drparg_WhlSpdLeReDir: accessed-variable=RP_Cpr_Powertrain_Data_SRI_Cpr_RxSignal_Powertrain.WhlSpdLeReDir
              drparg_WhlSpdLeReDir_Status: accessed-variable=RP_Cpr_Powertrain_Data_SRI_Cpr_RxSignal_Powertrain.WhlSpdLeReDir_Status
              drparg_WhlSpdReLePls: accessed-variable=RP_Cpr_Powertrain_Data_SRI_Cpr_RxSignal_Powertrain.WhlSpdReLePls
              drparg_WhlSpdReLePls_Status: accessed-variable=RP_Cpr_Powertrain_Data_SRI_Cpr_RxSignal_Powertrain.WhlSpdReLePls_Status
              drparg_WhlSpdReRiPls: accessed-variable=RP_Cpr_Powertrain_Data_SRI_Cpr_RxSignal_Powertrain.WhlSpdReRiPls
              drparg_WhlSpdReRiPls_Status: accessed-variable=RP_Cpr_Powertrain_Data_SRI_Cpr_RxSignal_Powertrain.WhlSpdReRiPls_Status
              drparg_WhlSpdRiFrntData: accessed-variable=RP_Cpr_Powertrain_Data_SRI_Cpr_RxSignal_Powertrain.WhlSpdRiFrntData
              drparg_WhlSpdRiFrntDataVld: accessed-variable=RP_Cpr_Powertrain_Data_SRI_Cpr_RxSignal_Powertrain.WhlSpdRiFrntDataVld
              drparg_WhlSpdRiFrntDir: accessed-variable=RP_Cpr_Powertrain_Data_SRI_Cpr_RxSignal_Powertrain.WhlSpdRiFrntDir
              drparg_WhlSpdRiFrntDir_Status: accessed-variable=RP_Cpr_Powertrain_Data_SRI_Cpr_RxSignal_Powertrain.WhlSpdRiFrntDir_Status
              drparg_WhlSpdRiReData: accessed-variable=RP_Cpr_Powertrain_Data_SRI_Cpr_RxSignal_Powertrain.WhlSpdRiReData
              drparg_WhlSpdRiReDataVld: accessed-variable=RP_Cpr_Powertrain_Data_SRI_Cpr_RxSignal_Powertrain.WhlSpdRiReDataVld
              drparg_WhlSpdRiReDir: accessed-variable=RP_Cpr_Powertrain_Data_SRI_Cpr_RxSignal_Powertrain.WhlSpdRiReDir
              drparg_WhlSpdRiReDir_Status: accessed-variable=RP_Cpr_Powertrain_Data_SRI_Cpr_RxSignal_Powertrain.WhlSpdRiReDir_Status
          9 x sync call, all with timeout=0.0:
            scp_GetRegValue: operation=RP_Port_Cdd_EvAdc_GetRegValue_VMON_BATT.GetRegValue
            scp_GetRegValue0: operation=RP_Port_Cdd_EvAdc_GetRegValue_VMON_IGN.GetRegValue
            scp_GetRegValue1: operation=RP_Port_Cdd_EvAdc_GetRegValue_TMON_SYS2.GetRegValue
            scp_GetRegValue2: operation=RP_Port_Cdd_EvAdc_GetRegValue_TMON_SYS1.GetRegValue
            scp_GetRegValue3: operation=RP_Port_Cdd_EvAdc_GetRegValue_VMON_3V3_GEPHY.GetRegValue
            scp_GetRegValue4: operation=RP_Port_Cdd_EvAdc_GetRegValue_VMON_1V0_GEPHY.GetRegValue
            scp_GetRegValue5: operation=RP_Port_Cdd_EvAdc_GetRegValue_J3_PMIC_8200_AMUX_OUT.GetRegValue
            scp_GetRegValue6: operation=RP_Port_Cdd_EvAdc_GetRegValue_PMIC_FS84_AMUX_OUT0.GetRegValue
            scp_Get_MsgStatus: operation=RP_Cpr_GetMsgStatusInfo_CSI_Cpr_RxMessageState.Get_RxMsgStatus
        Med_u_CBStatusEvt_DEM_CAMERA_CALIBRATION_FAILURE
        Med_u_CBStatusEvt_DEM_CAMERA_ONLINE_CALIBRATION_FAILURE
        Med_u_CBStatusEvt_DEM_DTC_ADC_All_Node_Missing
        Med_u_CBStatusEvt_DEM_DTC_ADC_Message_Alive_Counter_Error
        Med_u_CBStatusEvt_DEM_DTC_BCM_All_Node_Missing
        Med_u_CBStatusEvt_DEM_DTC_BCM_Brake_Lamp_Error
        Med_u_CBStatusEvt_DEM_DTC_BCM_EmgyLi_Fault
        Med_u_CBStatusEvt_DEM_DTC_BCM_FrntWiperSts_Fault
        Med_u_CBStatusEvt_DEM_DTC_BCM_Message_Alive_Counter_Error_40ms
        Med_u_CBStatusEvt_DEM_DTC_BCM_TurnIndcrLight_Fault
        Med_u_CBStatusEvt_DEM_DTC_EPS_APA_Epas_Fault
        Med_u_CBStatusEvt_DEM_DTC_EPS_ActualMotor_Invld
        Med_u_CBStatusEvt_DEM_DTC_EPS_Actual_Motor_Torq_Invld
        Med_u_CBStatusEvt_DEM_DTC_EPS_Actual_TorsionTorq_Invld
        Med_u_CBStatusEvt_DEM_DTC_EPS_All_Node_Missing
        Med_u_CBStatusEvt_DEM_DTC_EPS_Driver_handtorque_invalid
        Med_u_CBStatusEvt_DEM_DTC_EPS_Fault
        Med_u_CBStatusEvt_DEM_DTC_EPS_Message_Alive_Counter_Error_10ms
        Med_u_CBStatusEvt_DEM_DTC_EPS_Message_Alive_Counter_Error_20ms
        Med_u_CBStatusEvt_DEM_DTC_EPS_Pinionang_Fault
        Med_u_CBStatusEvt_DEM_DTC_EPS_Pinionang_Invld
        Med_u_CBStatusEvt_DEM_DTC_EPS_Sas_NOT_Cal
        Med_u_CBStatusEvt_DEM_DTC_EPS_Steer_AgSens_Fault
        Med_u_CBStatusEvt_DEM_DTC_EPS_Steering_wheelvibration_failure
        Med_u_CBStatusEvt_DEM_DTC_ESP_ABA_NOT_Available
        Med_u_CBStatusEvt_DEM_DTC_ESP_ABS_Fault
        Med_u_CBStatusEvt_DEM_DTC_ESP_AEB_NOT_Available
        Med_u_CBStatusEvt_DEM_DTC_ESP_AWB_NOT_Available
        Med_u_CBStatusEvt_DEM_DTC_ESP_All_Node_Missing
        Med_u_CBStatusEvt_DEM_DTC_ESP_Ebd_Failr
        Med_u_CBStatusEvt_DEM_DTC_ESP_Lat_Accel_Invld
        Med_u_CBStatusEvt_DEM_DTC_ESP_Long_Accel_Invld
        Med_u_CBStatusEvt_DEM_DTC_ESP_Message_Alive_Counter_Error
        Med_u_CBStatusEvt_DEM_DTC_ESP_Message_Alive_Counter_Error_100ms
        Med_u_CBStatusEvt_DEM_DTC_ESP_TCS_Fault
        Med_u_CBStatusEvt_DEM_DTC_ESP_Veh_Spd_Invld
        Med_u_CBStatusEvt_DEM_DTC_ESP_Yaw_Rate_Invld
        Med_u_CBStatusEvt_DEM_DTC_FR_All_Node_Missing
        Med_u_CBStatusEvt_DEM_DTC_Fradar_hardware_error
        Med_u_CBStatusEvt_DEM_DTC_Fradar_not_calibration_or_blockage
        Med_u_CBStatusEvt_DEM_DTC_Front_Radar_Alive_Counter_Error
        Med_u_CBStatusEvt_DEM_DTC_IB_Brk_Pedl_Invld
        Med_u_CBStatusEvt_DEM_DTC_IP_message_alive_counter_error
        Med_u_CBStatusEvt_DEM_DTC_IP_node_missing
        Med_u_CBStatusEvt_DEM_DTC_IP_warning_invalid
        Med_u_CBStatusEvt_DEM_DTC_J3_Camera_Blockage
        Med_u_CBStatusEvt_DEM_DTC_J3_Camera_Error
        Med_u_CBStatusEvt_DEM_DTC_J3_SOC_CPU_Error_PWM_Missing
        Med_u_CBStatusEvt_DEM_DTC_J3_SOC_Perception_Error
        Med_u_CBStatusEvt_DEM_DTC_J3_SOC_Safetylib_Error
        Med_u_CBStatusEvt_DEM_DTC_J3_SOC_System_Service_Error
        Med_u_CBStatusEvt_DEM_DTC_J3_Time_Sync_Error
        Med_u_CBStatusEvt_DEM_DTC_MCU_TEMP_INITIAL_HIGH
        Med_u_CBStatusEvt_DEM_DTC_Private_CAN_Bus_Off
        Med_u_CBStatusEvt_DEM_DTC_Public_CAN_Bus_Off
        Med_u_CBStatusEvt_DEM_DTC_RLR_Message_Alive_Counter_Error
        Med_u_CBStatusEvt_DEM_DTC_SRS_All_Node_Missing
        Med_u_CBStatusEvt_DEM_DTC_SRS_Drvr_BucSwt_Invld
        Med_u_CBStatusEvt_DEM_DTC_SRS_Message_Alive_Counter_Error
        Med_u_CBStatusEvt_DEM_DTC_VCU_Accr_Pedl_Posn_Invld
        Med_u_CBStatusEvt_DEM_DTC_VCU_All_Node_Missing
        Med_u_CBStatusEvt_DEM_DTC_VCU_Gear_Posn_Invld
        Med_u_CBStatusEvt_DEM_DTC_VCU_Message_Alive_Counter_Error
        Med_u_CBStatusEvt_DEM_DTC_Whl_Spd_Data_Invld
        Med_u_CBStatusEvt_DEM_DTC_Whl_Spd_Dir_Invld
        Med_u_CBStatusEvt_DEM_DTC_Whl_Spd_Pls_Invld
        Med_u_CBStatusEvt_DEM_J3_SYS_KERNEL_SW
        Med_u_CBStatusEvt_DEM_MCU_TEMP_EXT_HIGH
        Med_u_CBStatusEvt_DEM_MCU_TEMP_EXT_LOW
        Med_u_CBStatusEvt_DEM_SOCJ3_TEMP_EXT_HIGH
        Med_u_CBStatusEvt_DEM_VMON_BATT_HIGH
        Med_u_CBStatusEvt_DEM_VMON_BATT_LOW
        Med_u_CBStatusEvt_SPI_E_HARDWARE_ERROR
  swc implementation MedImplementation: programming-language=C, sw-version=1.0.0, vendor-id=0, behavior=Med_IB
    code-descriptors:
      code CodeGen: artifact-descriptors=[{short-label=Med_H, category=SWHDR}, {short-label=SWSRC, category=SWSRC}]
    resource consumption Med_Resource
      memory section CODE: sw-addrmethod=CODE
      memory section VAR_UNSPECIFIED: sw-addrmethod=VAR
